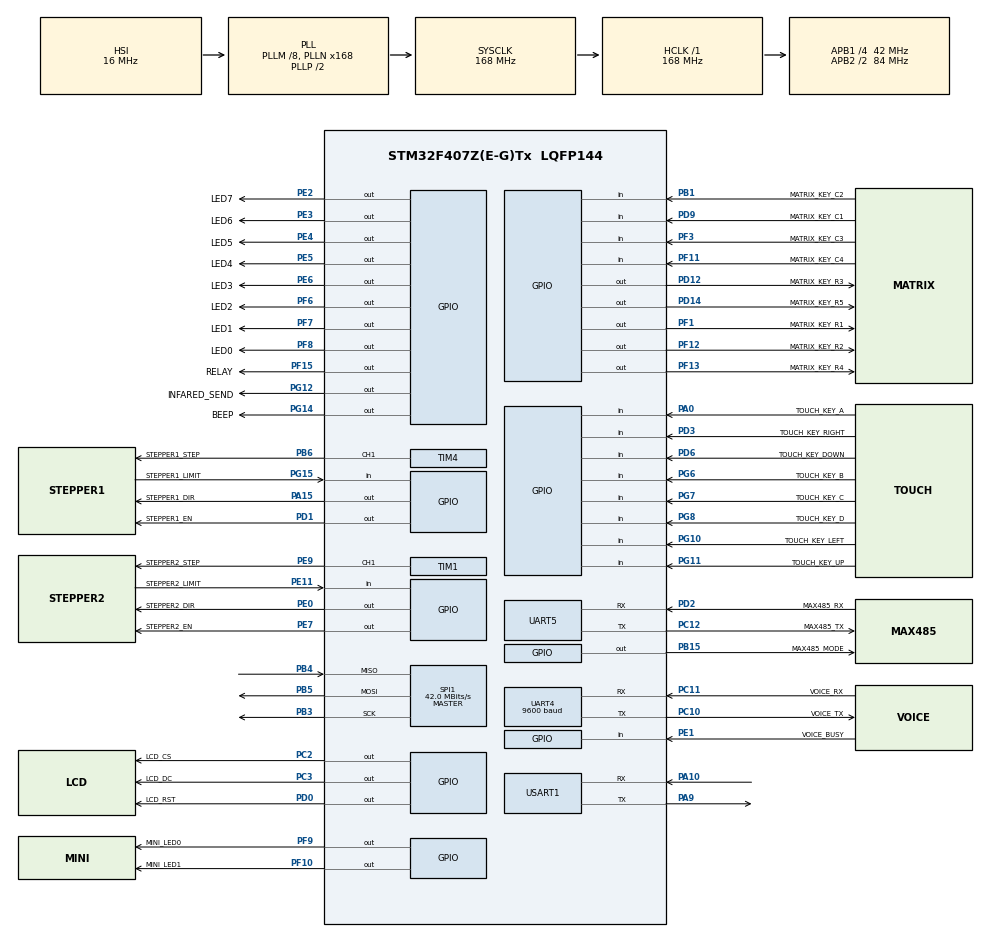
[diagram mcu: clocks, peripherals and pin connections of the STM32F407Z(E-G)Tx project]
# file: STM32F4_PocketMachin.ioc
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Dma.Request0=SPI1_RX
Dma.Request1=SPI1_TX
Dma.SPI1_RX.0.Direction=DMA_PERIPH_TO_MEMORY
Dma.SPI1_RX.0.FIFOMode=DMA_FIFOMODE_DISABLE
Dma.SPI1_RX.0.Instance=DMA2_Stream0
Dma.SPI1_RX.0.MemDataAlignment=DMA_MDATAALIGN_BYTE
Dma.SPI1_RX.0.MemInc=DMA_MINC_ENABLE
Dma.SPI1_RX.0.Mode=DMA_NORMAL
Dma.SPI1_RX.0.PeriphDataAlignment=DMA_PDATAALIGN_BYTE
Dma.SPI1_RX.0.PeriphInc=DMA_PINC_DISABLE
Dma.SPI1_RX.0.Priority=DMA_PRIORITY_LOW
Dma.SPI1_TX.1.Direction=DMA_MEMORY_TO_PERIPH
Dma.SPI1_TX.1.FIFOMode=DMA_FIFOMODE_DISABLE
Dma.SPI1_TX.1.Instance=DMA2_Stream3
Dma.SPI1_TX.1.MemDataAlignment=DMA_MDATAALIGN_BYTE
Dma.SPI1_TX.1.MemInc=DMA_MINC_ENABLE
Dma.SPI1_TX.1.Mode=DMA_NORMAL
Dma.SPI1_TX.1.PeriphDataAlignment=DMA_PDATAALIGN_BYTE
Dma.SPI1_TX.1.PeriphInc=DMA_PINC_DISABLE
Dma.SPI1_TX.1.Priority=DMA_PRIORITY_LOW
Mcu.Family=STM32F4
Mcu.Name=STM32F407Z(E-G)Tx
Mcu.Package=LQFP144
NVIC.DMA2_Stream0_IRQn=true\:0\:0\:true\:false\:true\:false\:true\:true
NVIC.DMA2_Stream3_IRQn=true\:0\:0\:true\:false\:true\:false\:true\:true
NVIC.PriorityGroup=NVIC_PRIORITYGROUP_4
NVIC.TIM1_BRK_TIM9_IRQn=true\:2\:0\:true\:false\:true\:true\:true\:true
NVIC.TIM4_IRQn=true\:2\:0\:true\:false\:true\:true\:true\:true
NVIC.TIM6_DAC_IRQn=true\:15\:0\:true\:false\:true\:true\:true\:true
NVIC.UART4_IRQn=true\:1\:0\:true\:false\:true\:true\:true\:true
NVIC.UART5_IRQn=true\:1\:0\:true\:false\:true\:true\:true\:true
NVIC.USART1_IRQn=true\:0\:0\:false\:false\:true\:true\:true\:true
PA0-WKUP.GPIO_Label=TOUCH_KEY_A
PA0-WKUP.GPIO_PuPd=GPIO_PULLUP
PA0-WKUP.Signal=GPIO_Input
PA10.Mode=Asynchronous
PA10.Signal=USART1_RX
PA13.Mode=Serial_Wire
PA13.Signal=SYS_JTMS-SWDIO
PA14.Mode=Serial_Wire
PA14.Signal=SYS_JTCK-SWCLK
PA15.GPIO_Label=STEPPER1_DIR
PA15.GPIO_PuPd=GPIO_PULLDOWN
PA15.Signal=GPIO_Output
PA9.Mode=Asynchronous
PA9.Signal=USART1_TX
PB1.GPIO_Label=MATRIX_KEY_C2
PB1.GPIO_PuPd=GPIO_PULLUP
PB1.Signal=GPIO_Input
PB15.GPIO_Label=MAX485_MODE
PB15.GPIO_PuPd=GPIO_PULLDOWN
PB15.Signal=GPIO_Output
PB3.Mode=Full_Duplex_Master
PB3.Signal=SPI1_SCK
PB4.Mode=Full_Duplex_Master
PB4.Signal=SPI1_MISO
PB5.Mode=Full_Duplex_Master
PB5.Signal=SPI1_MOSI
PB6.GPIO_Label=STEPPER1_STEP
PB6.Signal=S_TIM4_CH1
PC10.GPIO_Label=VOICE_TX
PC10.Mode=Asynchronous
PC10.Signal=UART4_TX
PC11.GPIO_Label=VOICE_RX
PC11.Mode=Asynchronous
PC11.Signal=UART4_RX
PC12.GPIO_Label=MAX485_TX
PC12.Mode=Asynchronous
PC12.Signal=UART5_TX
PC14-OSC32_IN.Mode=LSE-External-Oscillator
PC14-OSC32_IN.Signal=RCC_OSC32_IN
PC15-OSC32_OUT.Mode=LSE-External-Oscillator
PC15-OSC32_OUT.Signal=RCC_OSC32_OUT
PC2.GPIO_Label=LCD_CS
PC2.GPIO_PuPd=GPIO_PULLDOWN
PC2.GPIO_Speed=GPIO_SPEED_FREQ_HIGH
PC2.PinState=GPIO_PIN_RESET
PC2.Signal=GPIO_Output
PC3.GPIO_Label=LCD_DC
PC3.GPIO_PuPd=GPIO_PULLDOWN
PC3.GPIO_Speed=GPIO_SPEED_FREQ_HIGH
PC3.PinState=GPIO_PIN_RESET
PC3.Signal=GPIO_Output
PD0.GPIO_Label=LCD_RST
PD0.GPIO_PuPd=GPIO_PULLDOWN
PD0.PinState=GPIO_PIN_RESET
PD0.Signal=GPIO_Output
PD1.GPIO_Label=STEPPER1_EN
PD1.GPIO_PuPd=GPIO_PULLDOWN
PD1.GPIO_Speed=GPIO_SPEED_FREQ_LOW
PD1.PinState=GPIO_PIN_RESET
PD1.Signal=GPIO_Output
PD12.GPIO_Label=MATRIX_KEY_R3
PD12.GPIO_PuPd=GPIO_PULLUP
PD12.GPIO_Speed=GPIO_SPEED_FREQ_HIGH
PD12.PinState=GPIO_PIN_SET
PD12.Signal=GPIO_Output
PD14.GPIO_Label=MATRIX_KEY_R5
PD14.GPIO_PuPd=GPIO_PULLUP
PD14.GPIO_Speed=GPIO_SPEED_FREQ_HIGH
PD14.PinState=GPIO_PIN_SET
PD14.Signal=GPIO_Output
PD2.GPIO_Label=MAX485_RX
PD2.Mode=Asynchronous
PD2.Signal=UART5_RX
PD3.GPIO_Label=TOUCH_KEY_RIGHT
PD3.GPIO_PuPd=GPIO_PULLUP
PD3.Signal=GPIO_Input
PD6.GPIO_Label=TOUCH_KEY_DOWN
PD6.GPIO_PuPd=GPIO_PULLUP
PD6.Signal=GPIO_Input
PD9.GPIO_Label=MATRIX_KEY_C1
PD9.GPIO_PuPd=GPIO_PULLUP
PD9.Signal=GPIO_Input
PE0.GPIO_Label=STEPPER2_DIR
PE0.GPIO_PuPd=GPIO_PULLDOWN
PE0.GPIO_Speed=GPIO_SPEED_FREQ_LOW
PE0.Signal=GPIO_Output
PE1.GPIO_Label=VOICE_BUSY
PE1.GPIO_PuPd=GPIO_PULLDOWN
PE1.Signal=GPIO_Input
PE11.GPIO_Label=STEPPER2_LIMIT
PE11.GPIO_PuPd=GPIO_PULLUP
PE11.Signal=GPIO_Input
PE2.GPIO_Label=LED7
PE2.GPIO_PuPd=GPIO_PULLUP
PE2.PinState=GPIO_PIN_SET
PE2.Signal=GPIO_Output
PE3.GPIO_Label=LED6
PE3.GPIO_PuPd=GPIO_PULLUP
PE3.PinState=GPIO_PIN_SET
PE3.Signal=GPIO_Output
PE4.GPIO_Label=LED5
PE4.GPIO_PuPd=GPIO_PULLUP
PE4.PinState=GPIO_PIN_SET
PE4.Signal=GPIO_Output
PE5.GPIO_Label=LED4
PE5.GPIO_PuPd=GPIO_PULLUP
PE5.PinState=GPIO_PIN_SET
PE5.Signal=GPIO_Output
PE6.GPIO_Label=LED3
PE6.GPIO_PuPd=GPIO_PULLUP
PE6.PinState=GPIO_PIN_SET
PE6.Signal=GPIO_Output
PE7.GPIO_Label=STEPPER2_EN
PE7.GPIO_PuPd=GPIO_PULLDOWN
PE7.GPIO_Speed=GPIO_SPEED_FREQ_LOW
PE7.Signal=GPIO_Output
PE9.GPIO_Label=STEPPER2_STEP
PE9.Signal=S_TIM1_CH1
PF1.GPIO_Label=MATRIX_KEY_R1
PF1.GPIO_PuPd=GPIO_PULLUP
PF1.GPIO_Speed=GPIO_SPEED_FREQ_HIGH
PF1.PinState=GPIO_PIN_SET
PF1.Signal=GPIO_Output
PF10.GPIO_Label=MINI_LED1
PF10.GPIO_PuPd=GPIO_PULLUP
PF10.GPIO_Speed=GPIO_SPEED_FREQ_LOW
PF10.PinState=GPIO_PIN_SET
PF10.Signal=GPIO_Output
PF11.GPIO_Label=MATRIX_KEY_C4
PF11.GPIO_PuPd=GPIO_PULLUP
PF11.Signal=GPIO_Input
PF12.GPIO_Label=MATRIX_KEY_R2
PF12.GPIO_PuPd=GPIO_PULLUP
PF12.GPIO_Speed=GPIO_SPEED_FREQ_HIGH
PF12.PinState=GPIO_PIN_SET
PF12.Signal=GPIO_Output
PF13.GPIO_Label=MATRIX_KEY_R4
PF13.GPIO_PuPd=GPIO_PULLUP
PF13.GPIO_Speed=GPIO_SPEED_FREQ_HIGH
PF13.PinState=GPIO_PIN_SET
PF13.Signal=GPIO_Output
PF15.GPIO_Label=RELAY
PF15.GPIO_PuPd=GPIO_PULLDOWN
PF15.PinState=GPIO_PIN_RESET
PF15.Signal=GPIO_Output
PF3.GPIO_Label=MATRIX_KEY_C3
PF3.GPIO_PuPd=GPIO_PULLUP
PF3.Signal=GPIO_Input
PF6.GPIO_Label=LED2
PF6.GPIO_PuPd=GPIO_PULLUP
PF6.PinState=GPIO_PIN_SET
PF6.Signal=GPIO_Output
PF7.GPIO_Label=LED1
PF7.GPIO_PuPd=GPIO_PULLUP
PF7.PinState=GPIO_PIN_SET
PF7.Signal=GPIO_Output
PF8.GPIO_Label=LED0
PF8.GPIO_PuPd=GPIO_PULLUP
PF8.PinState=GPIO_PIN_SET
PF8.Signal=GPIO_Output
PF9.GPIO_Label=MINI_LED0
PF9.GPIO_ModeDefaultOutputPP=GPIO_MODE_OUTPUT_PP
PF9.GPIO_PuPd=GPIO_PULLUP
PF9.GPIO_Speed=GPIO_SPEED_FREQ_LOW
PF9.PinState=GPIO_PIN_SET
PF9.Signal=GPIO_Output
PG10.GPIO_Label=TOUCH_KEY_LEFT
PG10.GPIO_PuPd=GPIO_PULLUP
PG10.Signal=GPIO_Input
PG11.GPIO_Label=TOUCH_KEY_UP
PG11.GPIO_PuPd=GPIO_PULLUP
PG11.Signal=GPIO_Input
PG12.GPIO_Label=INFARED_SEND
PG12.GPIO_PuPd=GPIO_PULLDOWN
PG12.GPIO_Speed=GPIO_SPEED_FREQ_VERY_HIGH
PG12.PinState=GPIO_PIN_SET
PG12.Signal=GPIO_Output
PG14.GPIO_Label=BEEP
PG14.GPIO_PuPd=GPIO_PULLDOWN
PG14.Signal=GPIO_Output
PG15.GPIO_Label=STEPPER1_LIMIT
PG15.GPIO_PuPd=GPIO_PULLUP
PG15.Signal=GPIO_Input
PG6.GPIO_Label=TOUCH_KEY_B
PG6.GPIO_PuPd=GPIO_PULLUP
PG6.Signal=GPIO_Input
PG7.GPIO_Label=TOUCH_KEY_C
PG7.GPIO_PuPd=GPIO_PULLUP
PG7.Signal=GPIO_Input
PG8.GPIO_Label=TOUCH_KEY_D
PG8.GPIO_PuPd=GPIO_PULLUP
PG8.Signal=GPIO_Input
PH0-OSC_IN.Mode=HSE-External-Oscillator
PH0-OSC_IN.Signal=RCC_OSC_IN
PH1-OSC_OUT.Mode=HSE-External-Oscillator
PH1-OSC_OUT.Signal=RCC_OSC_OUT
ProjectManager.HeapSize=0x200
ProjectManager.StackSize=0x400
ProjectManager.TargetToolchain=MDK-ARM V5.32
RCC.48MHZClocksFreq_Value=84000000
RCC.AHBFreq_Value=168000000
RCC.APB1CLKDivider=RCC_HCLK_DIV4
RCC.APB1Freq_Value=42000000
RCC.APB1TimFreq_Value=84000000
RCC.APB2CLKDivider=RCC_HCLK_DIV2
RCC.APB2Freq_Value=84000000
RCC.APB2TimFreq_Value=168000000
RCC.CortexFreq_Value=168000000
RCC.HCLKFreq_Value=168000000
RCC.HSE_VALUE=25000000
RCC.HSI_VALUE=16000000
RCC.PLLM=8
RCC.PLLN=168
RCC.SYSCLKFreq_VALUE=168000000
RCC.SYSCLKSource=RCC_SYSCLKSOURCE_PLLCLK
RCC.VCOOutputFreq_Value=336000000
SH.S_TIM1_CH1.0=TIM1_CH1,Output Compare1 CH1
SH.S_TIM4_CH1.0=TIM4_CH1,Output Compare1 CH1
SPI1.BaudRatePrescaler=SPI_BAUDRATEPRESCALER_2
SPI1.CLKPolarity=SPI_POLARITY_HIGH
SPI1.CalculateBaudRate=42.0 MBits/s
SPI1.Direction=SPI_DIRECTION_2LINES
SPI1.Mode=SPI_MODE_MASTER
SPI1.VirtualType=VM_MASTER
TIM1.AutoReloadPreload=TIM_AUTORELOAD_PRELOAD_ENABLE
TIM1.Channel-Output\ Compare1\ CH1=TIM_CHANNEL_1
TIM1.OCMode_1=TIM_OCMODE_TOGGLE
TIM1.OCPolarity_1=TIM_OCPOLARITY_LOW
TIM1.Period=0xFFFF
TIM1.Prescaler=84-1
TIM4.AutoReloadPreload=TIM_AUTORELOAD_PRELOAD_ENABLE
TIM4.Channel-Output\ Compare1\ CH1=TIM_CHANNEL_1
TIM4.OCMode_1=TIM_OCMODE_TOGGLE
TIM4.OCPolarity_1=TIM_OCPOLARITY_LOW
TIM4.Period=0xFFFF
TIM4.Prescaler=84-1
TIM6.AutoReloadPreload=TIM_AUTORELOAD_PRELOAD_ENABLE
TIM6.Period=1000-1
TIM6.Prescaler=84-1
UART4.BaudRate=9600
UART4.VirtualMode=Asynchronous
UART5.VirtualMode=Asynchronous
USART1.VirtualMode=VM_ASYNC
VP_TIM1_VS_ClockSourceINT.Mode=Internal
VP_TIM4_VS_ClockSourceINT.Mode=Internal
VP_TIM6_VS_ClockSourceINT.Mode=Enable_Timer
board=custom

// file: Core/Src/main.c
/* USER CODE BEGIN Header */
/**
 ******************************************************************************
 * @file           : main.c
 * @brief          : Main program body
 ******************************************************************************
 * @attention
 *
 * Copyright (c) 2023 STMicroelectronics.
 * All rights reserved.
 *
 * This software is licensed under terms that can be found in the LICENSE file
 * in the root directory of this software component.
 * If no LICENSE file comes with this software, it is provided AS-IS.
 *
 ******************************************************************************
 */
/* USER CODE END Header */
#include "main.h"
#include "dma.h"
#include "spi.h"
#include "tim.h"
#include "usart.h"
#include "gpio.h"

/* USER CODE BEGIN Includes */
#include ".\SmartTimer\smarttimer.h"
#include "app.h"
/* USER CODE END Includes */

void SystemClock_Config(void);

int main(void)
{

  /* MCU Configuration--------------------------------------------------------*/

  /* Reset of all peripherals, Initializes the Flash interface and the Systick. */
  HAL_Init();

  /* Configure the system clock */
  SystemClock_Config();

  /* Initialize all configured peripherals */
  MX_GPIO_Init();
  MX_DMA_Init();
  MX_TIM6_Init();
  MX_SPI1_Init();
  MX_UART5_Init();
  MX_UART4_Init();
  MX_TIM1_Init();
  MX_TIM4_Init();
  MX_USART1_UART_Init();
  /* USER CODE BEGIN 2 */

  stim_init();                   // 任务调度器初始化
  HAL_TIM_Base_Start_IT(&htim6); // 启动任务调度器时钟 （定时器）
  stim_start_task();             // 启动任务调度器（任务）

  /* USER CODE END 2 */

  /* Infinite loop */
  while (1)
  {

    /* USER CODE BEGIN 3 */

    stim_mainloop(); // 任务调度器时间处理
  }
  /* USER CODE END 3 */
}

void SystemClock_Config(void)
{
  RCC_OscInitTypeDef RCC_OscInitStruct = {0};
  RCC_ClkInitTypeDef RCC_ClkInitStruct = {0};

  /** Configure the main internal regulator output voltage
  */
  __HAL_RCC_PWR_CLK_ENABLE();
  __HAL_PWR_VOLTAGESCALING_CONFIG(PWR_REGULATOR_VOLTAGE_SCALE1);

  /** Initializes the RCC Oscillators according to the specified parameters
  * in the RCC_OscInitTypeDef structure.
  */
  RCC_OscInitStruct.OscillatorType = RCC_OSCILLATORTYPE_HSI;
  RCC_OscInitStruct.HSIState = RCC_HSI_ON;
  RCC_OscInitStruct.HSICalibrationValue = RCC_HSICALIBRATION_DEFAULT;
  RCC_OscInitStruct.PLL.PLLState = RCC_PLL_ON;
  RCC_OscInitStruct.PLL.PLLSource = RCC_PLLSOURCE_HSI;
  RCC_OscInitStruct.PLL.PLLM = 8;
  RCC_OscInitStruct.PLL.PLLN = 168;
  RCC_OscInitStruct.PLL.PLLP = RCC_PLLP_DIV2;
  RCC_OscInitStruct.PLL.PLLQ = 4;
  if (HAL_RCC_OscConfig(&RCC_OscInitStruct) != HAL_OK)
  {
    Error_Handler();
  }

  /** Initializes the CPU, AHB and APB buses clocks
  */
  RCC_ClkInitStruct.ClockType = RCC_CLOCKTYPE_HCLK|RCC_CLOCKTYPE_SYSCLK
                              |RCC_CLOCKTYPE_PCLK1|RCC_CLOCKTYPE_PCLK2;
  RCC_ClkInitStruct.SYSCLKSource = RCC_SYSCLKSOURCE_PLLCLK;
  RCC_ClkInitStruct.AHBCLKDivider = RCC_SYSCLK_DIV1;
  RCC_ClkInitStruct.APB1CLKDivider = RCC_HCLK_DIV4;
  RCC_ClkInitStruct.APB2CLKDivider = RCC_HCLK_DIV2;

  if (HAL_RCC_ClockConfig(&RCC_ClkInitStruct, FLASH_LATENCY_5) != HAL_OK)
  {
    Error_Handler();
  }
}

void Error_Handler(void)
{
  __disable_irq();
  while (1)
  {
  }
}
